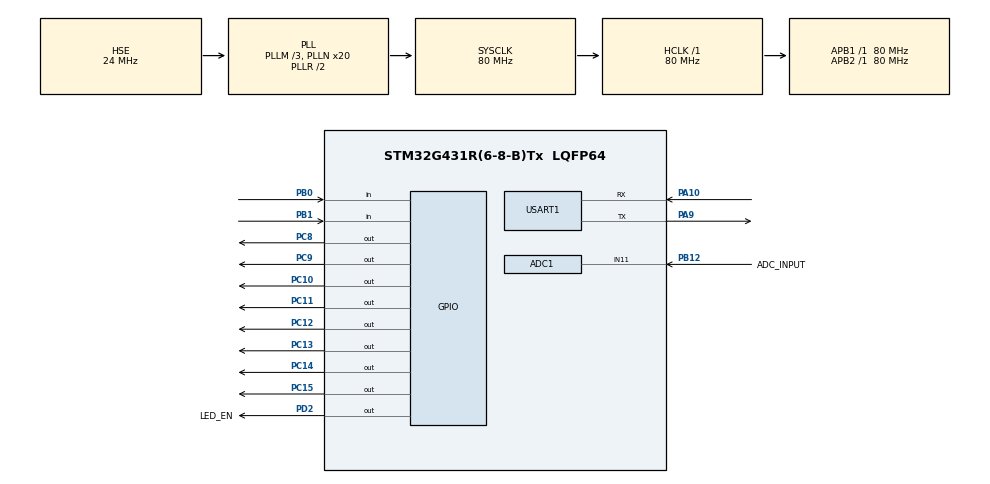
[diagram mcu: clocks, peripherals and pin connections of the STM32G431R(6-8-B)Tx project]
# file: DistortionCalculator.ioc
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ADC1.Channel-1\#ChannelRegularConversion=ADC_CHANNEL_11
ADC1.DMAContinuousRequests=ENABLE
ADC1.ExternalTrigConv=ADC_EXTERNALTRIG_T2_TRGO
ADC1.NbrOfConversionFlag=1
ADC1.OffsetNumber-1\#ChannelRegularConversion=ADC_OFFSET_NONE
ADC1.Overrun=ADC_OVR_DATA_PRESERVED
ADC1.Rank-1\#ChannelRegularConversion=1
ADC1.SamplingTime-1\#ChannelRegularConversion=ADC_SAMPLETIME_2CYCLES_5
ADC1.master=1
Dma.ADC1.0.Direction=DMA_PERIPH_TO_MEMORY
Dma.ADC1.0.EventEnable=DISABLE
Dma.ADC1.0.Instance=DMA1_Channel1
Dma.ADC1.0.MemDataAlignment=DMA_MDATAALIGN_HALFWORD
Dma.ADC1.0.MemInc=DMA_MINC_ENABLE
Dma.ADC1.0.Mode=DMA_NORMAL
Dma.ADC1.0.PeriphDataAlignment=DMA_PDATAALIGN_HALFWORD
Dma.ADC1.0.PeriphInc=DMA_PINC_DISABLE
Dma.ADC1.0.Polarity=HAL_DMAMUX_REQ_GEN_RISING
Dma.ADC1.0.Priority=DMA_PRIORITY_LOW
Dma.ADC1.0.RequestNumber=1
Dma.ADC1.0.SignalID=NONE
Dma.ADC1.0.SyncEnable=DISABLE
Dma.ADC1.0.SyncPolarity=HAL_DMAMUX_SYNC_NO_EVENT
Dma.ADC1.0.SyncRequestNumber=1
Dma.ADC1.0.SyncSignalID=NONE
Dma.Request0=ADC1
Mcu.Family=STM32G4
Mcu.Name=STM32G431R(6-8-B)Tx
Mcu.Package=LQFP64
NVIC.ADC1_2_IRQn=true\:0\:0\:false\:false\:true\:true\:true\:true
NVIC.DMA1_Channel1_IRQn=true\:0\:0\:false\:false\:true\:false\:true\:true
NVIC.PriorityGroup=NVIC_PRIORITYGROUP_4
NVIC.TIM2_IRQn=true\:0\:0\:false\:false\:true\:true\:true\:true
NVIC.USART1_IRQn=true\:0\:0\:false\:false\:true\:true\:true\:true
PA10.Mode=Asynchronous
PA10.Signal=USART1_RX
PA13.Mode=Serial_Wire
PA13.Signal=SYS_JTMS-SWDIO
PA14.Mode=Serial_Wire
PA14.Signal=SYS_JTCK-SWCLK
PA9.Mode=Asynchronous
PA9.Signal=USART1_TX
PB0.Signal=GPIO_Input
PB1.Signal=GPIO_Input
PB12.GPIO_Label=ADC_INPUT
PB12.Mode=IN11-Single-Ended
PB12.Signal=ADC1_IN11
PC10.Signal=GPIO_Output
PC11.Signal=GPIO_Output
PC12.Signal=GPIO_Output
PC13.Signal=GPIO_Output
PC14-OSC32_IN.Signal=GPIO_Output
PC15-OSC32_OUT.Signal=GPIO_Output
PC8.Signal=GPIO_Output
PC9.Signal=GPIO_Output
PD2.GPIO_Label=LED_EN
PD2.PinState=GPIO_PIN_SET
PD2.Signal=GPIO_Output
PF0-OSC_IN.Mode=HSE-External-Oscillator
PF0-OSC_IN.Signal=RCC_OSC_IN
PF1-OSC_OUT.Mode=HSE-External-Oscillator
PF1-OSC_OUT.Signal=RCC_OSC_OUT
ProjectManager.HeapSize=0x200
ProjectManager.StackSize=0x400
ProjectManager.TargetToolchain=MDK-ARM V5.32
RCC.ADC12Freq_Value=80000000
RCC.AHBFreq_Value=80000000
RCC.APB1Freq_Value=80000000
RCC.APB1TimFreq_Value=80000000
RCC.APB2Freq_Value=80000000
RCC.APB2TimFreq_Value=80000000
RCC.CortexFreq_Value=80000000
RCC.EXTERNAL_CLOCK_VALUE=12288000
RCC.HCLKFreq_Value=80000000
RCC.HSE_VALUE=24000000
RCC.HSI48_VALUE=48000000
RCC.HSI_VALUE=16000000
RCC.LSE_VALUE=32768
RCC.PLLM=RCC_PLLM_DIV3
RCC.PLLN=20
RCC.PLLSourceVirtual=RCC_PLLSOURCE_HSE
RCC.SYSCLKFreq_VALUE=80000000
RCC.SYSCLKSource=RCC_SYSCLKSOURCE_PLLCLK
RCC.USBFreq_Value=80000000
RCC.VCOOutputFreq_Value=160000000
STMicroelectronics.X-CUBE-ALGOBUILD.1.4.0.LibraryCcDSPOoLibraryJjDSPOoLibrary=true
TIM2.PeriodNoDither=98-1
TIM2.Prescaler=8-1
TIM2.TIM_MasterOutputTrigger=TIM_TRGO_UPDATE
TIM2.TIM_MasterSlaveMode=TIM_MASTERSLAVEMODE_DISABLE
USART1.VirtualMode-Asynchronous=VM_ASYNC
VP_STMicroelectronics.X-CUBE-ALGOBUILD_VS_DSPOoLibraryJjLibrary_1.4.0_1.4.0.Mode=DSPOoLibraryJjLibrary
VP_SYS_VS_DBSignals.Mode=DisableDeadBatterySignals
VP_TIM2_VS_ClockSourceINT.Mode=Internal
board=custom

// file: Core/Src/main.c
/* USER CODE BEGIN Header */
/**
 ******************************************************************************
 * @file           : main.c
 * @brief          : Main program body
 ******************************************************************************
 * @attention
 *
 * Copyright (c) 2025 STMicroelectronics.
 * All rights reserved.
 *
 * This software is licensed under terms that can be found in the LICENSE file
 * in the root directory of this software component.
 * If no LICENSE file comes with this software, it is provided AS-IS.
 *
 ******************************************************************************
 */
/* USER CODE END Header */
#include "main.h"
#include "adc.h"
#include "dma.h"
#include "tim.h"
#include "usart.h"
#include "gpio.h"

/* USER CODE BEGIN Includes */
#include "global.h"
/* USER CODE END Includes */

void SystemClock_Config(void);

int main(void)
{

  /* MCU Configuration--------------------------------------------------------*/

  /* Reset of all peripherals, Initializes the Flash interface and the Systick. */
  HAL_Init();

  /* Configure the system clock */
  SystemClock_Config();

  /* Initialize all configured peripherals */
  MX_GPIO_Init();
  MX_DMA_Init();
  MX_ADC1_Init();
  MX_TIM2_Init();
  MX_USART1_UART_Init();
  /* USER CODE BEGIN 2 */
  Main_Task_Init();
  /* USER CODE END 2 */

  /* Infinite loop */
  /* USER CODE BEGIN WHILE */
    while (1)
    {
        Main_Task();
    /* USER CODE END WHILE */

    }
}

void SystemClock_Config(void)
{
  RCC_OscInitTypeDef RCC_OscInitStruct = {0};
  RCC_ClkInitTypeDef RCC_ClkInitStruct = {0};

  /** Configure the main internal regulator output voltage
  */
  HAL_PWREx_ControlVoltageScaling(PWR_REGULATOR_VOLTAGE_SCALE1);

  /** Initializes the RCC Oscillators according to the specified parameters
  * in the RCC_OscInitTypeDef structure.
  */
  RCC_OscInitStruct.OscillatorType = RCC_OSCILLATORTYPE_HSE;
  RCC_OscInitStruct.HSEState = RCC_HSE_ON;
  RCC_OscInitStruct.PLL.PLLState = RCC_PLL_ON;
  RCC_OscInitStruct.PLL.PLLSource = RCC_PLLSOURCE_HSE;
  RCC_OscInitStruct.PLL.PLLM = RCC_PLLM_DIV3;
  RCC_OscInitStruct.PLL.PLLN = 20;
  RCC_OscInitStruct.PLL.PLLP = RCC_PLLP_DIV2;
  RCC_OscInitStruct.PLL.PLLQ = RCC_PLLQ_DIV2;
  RCC_OscInitStruct.PLL.PLLR = RCC_PLLR_DIV2;
  if (HAL_RCC_OscConfig(&RCC_OscInitStruct) != HAL_OK)
  {
    Error_Handler();
  }

  /** Initializes the CPU, AHB and APB buses clocks
  */
  RCC_ClkInitStruct.ClockType = RCC_CLOCKTYPE_HCLK|RCC_CLOCKTYPE_SYSCLK
                              |RCC_CLOCKTYPE_PCLK1|RCC_CLOCKTYPE_PCLK2;
  RCC_ClkInitStruct.SYSCLKSource = RCC_SYSCLKSOURCE_PLLCLK;
  RCC_ClkInitStruct.AHBCLKDivider = RCC_SYSCLK_DIV1;
  RCC_ClkInitStruct.APB1CLKDivider = RCC_HCLK_DIV1;
  RCC_ClkInitStruct.APB2CLKDivider = RCC_HCLK_DIV1;

  if (HAL_RCC_ClockConfig(&RCC_ClkInitStruct, FLASH_LATENCY_2) != HAL_OK)
  {
    Error_Handler();
  }
}

void Error_Handler(void)
{
    __disable_irq();
    while (1)
    {
    }
}
